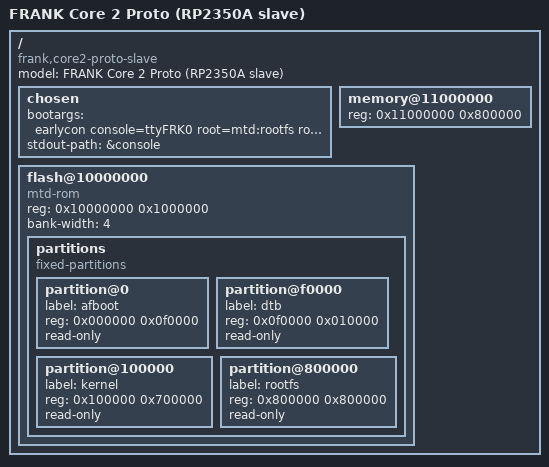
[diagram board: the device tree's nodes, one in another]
// SPDX-License-Identifier: GPL-2.0
/*
 * FRANK Core 2 Proto, slave half (U6, RP2350A) -- the half that runs Linux.
 *
 * Copyright (c) 2026 Mikhail Matveev <xtreme@rh1.tech>
 */

/dts-v1/;
#include "rp2350.dtsi"

/ {
	model = "FRANK Core 2 Proto (RP2350A slave)";
	compatible = "frank,core2-proto-slave", "raspberrypi,rp2350";

	chosen {
		/*
		 * root=mtd:rootfs, by name rather than mtd3, so renumbering the
		 * partitions above cannot silently boot the wrong one.
		 *
		 * The kernel routes this without a block device: parse_root_device()
		 * returns Root_Generic for anything starting "mtd", and romfs
		 * mounts the MTD directly (ROMFS_BACKED_BY_MTD). That is the whole
		 * point -- romfs on an MTD that can be pointed at gives every
		 * binary a direct mapping of flash, so the text is executed in
		 * place and costs no RAM. Through a block device it would be read
		 * into page cache instead, and on 8 MB that is the difference
		 * between running and not.
		 *
		 * rootfstype is needed because Root_Generic mounts by name; ro
		 * because romfs has no write path and saying so keeps the failure
		 * at mount time rather than on the first write.
		 */
		bootargs = "earlycon console=ttyFRK0 root=mtd:rootfs rootfstype=romfs ro";
		stdout-path = &console;
	};

	/*
	 * System RAM is the 8 MB of external PSRAM at the QMI chip-select 1
	 * window, and nothing else.
	 *
	 * The 520 kB of internal SRAM is deliberately absent. It belongs to
	 * core 1 -- its code, its stack and the console rings -- and listing it
	 * here would let the kernel allocate on top of them. It is also the one
	 * region where LDREX/STREX work, which is why core 1's structures live
	 * there and the kernel's do not.
	 */
	memory@11000000 {
		device_type = "memory";
		reg = <0x11000000 0x800000>;
	};

	/*
	 * The 16 MB QSPI flash, as memory rather than as a device.
	 *
	 * QMI keeps chip-select 0 mapped read-only at 0x10000000, so the flash
	 * is addressable the way ROM is. "mtd-rom" gives it to physmap as
	 * map_rom, which implements mtd->_point -- and that is the whole point:
	 * romfs on an MTD that can be pointed at hands NOMMU a direct mapping
	 * (fs/romfs/mmap-nommu.c), so program text executes in place from flash
	 * and costs no RAM at all.
	 *
	 * That matters more here than it would anywhere else. With 8 MB of
	 * PSRAM, a userspace in a RAM-resident initramfs spends 2 MB of it
	 * permanently, and one loaded from a block device would have to copy
	 * every binary in -- including a private copy of libc.so per process,
	 * because a block-backed filesystem cannot be pointed at either.
	 */
	flash@10000000 {
		compatible = "mtd-rom";
		reg = <0x10000000 0x1000000>;
		bank-width = <4>;
		#address-cells = <1>;
		#size-cells = <1>;

		partitions {
			compatible = "fixed-partitions";
			#address-cells = <1>;
			#size-cells = <1>;

			/* Matches the offsets tools/flash-slave.sh writes. */
			partition@0 {
				label = "afboot";
				reg = <0x000000 0x0f0000>;
				read-only;
			};

			partition@f0000 {
				label = "dtb";
				reg = <0x0f0000 0x010000>;
				read-only;
			};

			partition@100000 {
				label = "kernel";
				reg = <0x100000 0x700000>;
				read-only;
			};

			partition@800000 {
				label = "rootfs";
				reg = <0x800000 0x800000>;
				read-only;
			};
		};
	};
};
